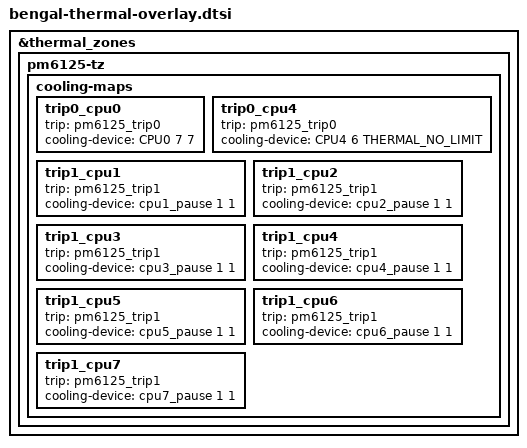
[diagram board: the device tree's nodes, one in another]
#include <dt-bindings/thermal/thermal.h>

&thermal_zones {
	pm6125-tz {
		cooling-maps {
			trip0_cpu0 {
				trip = <&pm6125_trip0>;
				cooling-device = <&CPU0 7 7>;
			};

			trip0_cpu4 {
				trip = <&pm6125_trip0>;
				cooling-device = <&CPU4 6 THERMAL_NO_LIMIT>;
			};

			trip1_cpu1 {
				trip = <&pm6125_trip1>;
				cooling-device = <&cpu1_pause 1 1>;
			};

			trip1_cpu2 {
				trip = <&pm6125_trip1>;
				cooling-device = <&cpu2_pause 1 1>;
			};

			trip1_cpu3 {
				trip = <&pm6125_trip1>;
				cooling-device = <&cpu3_pause 1 1>;
			};

			trip1_cpu4 {
				trip = <&pm6125_trip1>;
				cooling-device = <&cpu4_pause 1 1>;
			};

			trip1_cpu5 {
				trip = <&pm6125_trip1>;
				cooling-device = <&cpu5_pause 1 1>;
			};

			trip1_cpu6 {
				trip = <&pm6125_trip1>;
				cooling-device = <&cpu6_pause 1 1>;
			};

			trip1_cpu7 {
				trip = <&pm6125_trip1>;
				cooling-device = <&cpu7_pause 1 1>;
			};
		};
	};
};
